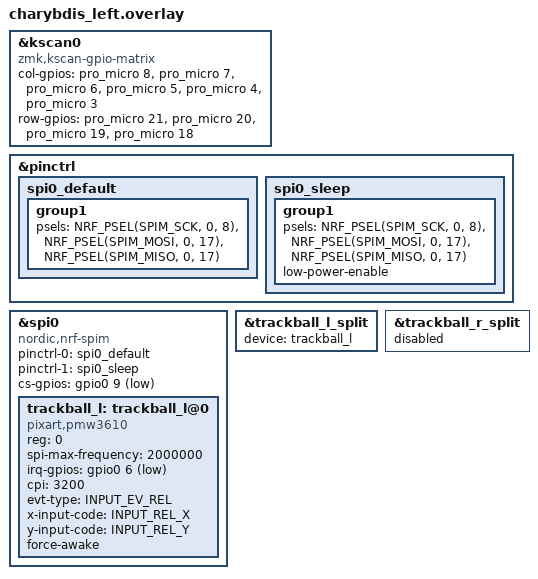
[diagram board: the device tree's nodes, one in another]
#include "charybdis.dtsi"
#include "charybdis_3610.dtsi"
#include "charybdis_zplit.dtsi"
#include <dt-bindings/zmk/input_transform.h>

&kscan0 {
	compatible = "zmk,kscan-gpio-matrix";
	
	col-gpios
		= <&pro_micro 8 GPIO_ACTIVE_HIGH>
		, <&pro_micro 7 GPIO_ACTIVE_HIGH>
		, <&pro_micro 6 GPIO_ACTIVE_HIGH>
		, <&pro_micro 5 GPIO_ACTIVE_HIGH>
		, <&pro_micro 4 GPIO_ACTIVE_HIGH>
		, <&pro_micro 3 GPIO_ACTIVE_HIGH>
		;

	row-gpios
		= <&pro_micro 21 (GPIO_ACTIVE_HIGH | GPIO_PULL_DOWN)>
		, <&pro_micro 20 (GPIO_ACTIVE_HIGH | GPIO_PULL_DOWN)>
		, <&pro_micro 19 (GPIO_ACTIVE_HIGH | GPIO_PULL_DOWN)>
		, <&pro_micro 18 (GPIO_ACTIVE_HIGH | GPIO_PULL_DOWN)>
		;
};

&pinctrl {
    spi0_default: spi0_default {
        group1 {
            psels = <NRF_PSEL(SPIM_SCK, 0, 8)>,
                <NRF_PSEL(SPIM_MOSI, 0, 17)>,
                <NRF_PSEL(SPIM_MISO, 0, 17)>;
        };
    };

    spi0_sleep: spi0_sleep {
        group1 {
            psels = <NRF_PSEL(SPIM_SCK, 0, 8)>,
                <NRF_PSEL(SPIM_MOSI, 0, 17)>,
                <NRF_PSEL(SPIM_MISO, 0, 17)>;
            low-power-enable;
        };
    };
};

&spi0 {
    compatible = "nordic,nrf-spim";
    status = "okay";
    pinctrl-0 = <&spi0_default>;
    pinctrl-1 = <&spi0_sleep>;
    pinctrl-names = "default", "sleep";
    cs-gpios = <&gpio0 9 GPIO_ACTIVE_LOW>;

    trackball_l: trackball_l@0 {
        compatible = "pixart,pmw3610";
        status = "okay";
        reg = <0>;
        spi-max-frequency = <2000000>;
        irq-gpios = <&gpio0 6 (GPIO_ACTIVE_LOW | GPIO_PULL_UP)>;
        cpi = <3200>;
        evt-type = <INPUT_EV_REL>;
        x-input-code = <INPUT_REL_X>;
        y-input-code = <INPUT_REL_Y>;

        force-awake;
        /* keep the sensor awake while ZMK activity state is ACTIVE,
           fallback to normal downshift mode after ZMK goes into IDLE / SLEEP mode.
           thus, the sensor would be a `wakeup-source` */
    };
};

&trackball_l_split {
	device = <&trackball_l>;
};

&trackball_r_split {
	status = "disabled";
};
